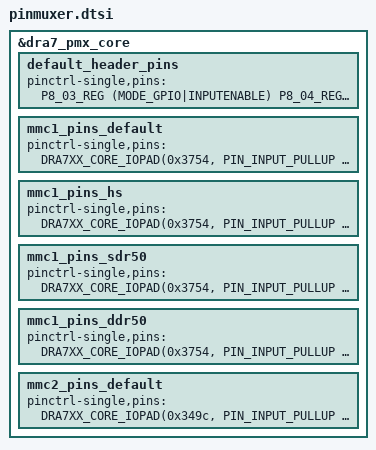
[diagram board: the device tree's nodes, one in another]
&dra7_pmx_core {
    //==============================================================================================
    //pin groups that are accessible via the headers -----------------------------------------------
    //==============================================================================================

    // Default grp: set all unused to GPIO (in). If you want to use any pin in a different way, 
    // comment it out here, put it in a different grp, and then connect the grp to a device in
    // the tree

    &default_header_pins: default_header_pins {  
        pinctrl-single,pins = < 
            P8_03_REG (MODE_GPIO|INPUTENABLE)
            P8_04_REG (MODE_GPIO|INPUTENABLE)
            P8_05_REG (MODE_GPIO|INPUTENABLE)
            P8_06_REG (MODE_GPIO|INPUTENABLE)
            P8_07_REG (MODE_GPIO|INPUTENABLE)
            P8_08_REG (MODE_GPIO|INPUTENABLE)
            P8_09_REG (MODE_GPIO|INPUTENABLE)
            P8_10_REG (MODE_GPIO|INPUTENABLE)

            P8_11_REG (MODE_GPIO|INPUTENABLE)
            P8_12_REG (MODE_GPIO|INPUTENABLE)
            P8_13_REG (MODE_GPIO|INPUTENABLE)
            P8_14_REG (MODE_GPIO|INPUTENABLE)
            P8_15A_REG (MODE_GPIO|INPUTENABLE)
            P8_15B_REG (MODE_OFF)
            P8_16_REG (MODE_GPIO|INPUTENABLE)
            P8_17_REG (MODE_GPIO|INPUTENABLE)
            P8_18_REG (MODE_GPIO|INPUTENABLE)
            P8_19_REG (MODE_GPIO|INPUTENABLE)

            P8_20_REG (MODE_GPIO|INPUTENABLE)
            P8_21_REG (MODE_GPIO|INPUTENABLE)
            P8_22_REG (MODE_GPIO|INPUTENABLE)
            P8_23_REG (MODE_GPIO|INPUTENABLE)
            P8_24_REG (MODE_GPIO|INPUTENABLE)
            P8_25_REG (MODE_GPIO|INPUTENABLE)
            P8_26_REG (MODE_GPIO|INPUTENABLE)
            P8_27A_REG (MODE_GPIO|INPUTENABLE)
            P8_27B_REG (MODE_OFF)
            P8_28A_REG (MODE_GPIO|INPUTENABLE)
            P8_28B_REG (MODE_OFF)
            P8_29A_REG (MODE_GPIO|INPUTENABLE)
            P8_29B_REG (MODE_OFF)

            P8_30A_REG (MODE_GPIO|INPUTENABLE)
            P8_30B_REG (MODE_OFF)
            P8_31A_REG (MODE_GPIO|INPUTENABLE)
            P8_31B_REG (MODE_OFF)
            P8_32A_REG (MODE_GPIO|INPUTENABLE)
            P8_32B_REG (MODE_OFF)
            P8_33A_REG (MODE_GPIO|INPUTENABLE)
            P8_33B_REG (MODE_OFF)
            P8_34A_REG (MODE_GPIO|INPUTENABLE)
            P8_34B_REG (MODE_OFF)
            P8_35A_REG (MODE_GPIO|INPUTENABLE)
            P8_35B_REG (MODE_OFF)
            P8_36A_REG (MODE_GPIO|INPUTENABLE)
            P8_36B_REG (MODE_OFF)
            P8_37A_REG (MODE_GPIO|INPUTENABLE)
            P8_37B_REG (MODE_OFF)
            P8_38A_REG (MODE_GPIO|INPUTENABLE)
            P8_38B_REG (MODE_OFF)
            P8_39_REG  (MODE_GPIO|INPUTENABLE)

            P8_40_REG (MODE_GPIO|INPUTENABLE)
            P8_41_REG (MODE_GPIO|INPUTENABLE)
            P8_42_REG (MODE_GPIO|INPUTENABLE)
            P8_43_REG (MODE_GPIO|INPUTENABLE)
            P8_44_REG (MODE_GPIO|INPUTENABLE)
            P8_45A_REG (MODE_GPIO|INPUTENABLE)
            P8_45B_REG (MODE_OFF)
            P8_46A_REG (MODE_GPIO|INPUTENABLE)
            P8_46B_REG (MODE_OFF)

            P9_11A_REG (MODE_GPIO|INPUTENABLE)
            P9_11B_REG (MODE_OFF)
            P9_12_REG (MODE_GPIO|INPUTENABLE)
            P9_13A_REG (MODE_GPIO|INPUTENABLE)
            P9_13B_REG (MODE_OFF)
            P9_14_REG (MODE_GPIO|INPUTENABLE)
            P9_15_REG (MODE_GPIO|INPUTENABLE)
            P9_16_REG (MODE_GPIO|INPUTENABLE)
            P9_17A_REG (MODE_GPIO|INPUTENABLE)
            P9_17B_REG (MODE_OFF)
            P9_18A_REG (MODE_GPIO|INPUTENABLE)
            P9_18B_REG (MODE_OFF)
            P9_19A_REG (MODE_GPIO|INPUTENABLE)
            P9_19B_REG (MODE_OFF)

            P9_20A_REG (MODE_GPIO|INPUTENABLE)
            P9_20B_REG (MODE_OFF)
            P9_21A_REG (MODE_GPIO|INPUTENABLE)
            P9_21B_REG (MODE_OFF)
            P9_22A_REG (MODE_GPIO|INPUTENABLE)
            P9_22B_REG (MODE_OFF)
            P9_23_REG (MODE_GPIO|INPUTENABLE)
            P9_24_REG (MODE_GPIO|INPUTENABLE)
            P9_25_REG (MODE_GPIO|INPUTENABLE)
            P9_26A_REG (MODE_GPIO|INPUTENABLE)
            P9_26B_REG (MODE_OFF)
            P9_27A_REG (MODE_GPIO|INPUTENABLE)
            P9_27B_REG (MODE_OFF)
            P9_28_REG (MODE_GPIO|INPUTENABLE)
            P9_29A_REG (MODE_GPIO|INPUTENABLE)
            P9_29B_REG (MODE_OFF)
            P9_30_REG (MODE_GPIO|INPUTENABLE)

            P9_31A_REG (MODE_GPIO|INPUTENABLE)
            P9_31B_REG (MODE_OFF)

            P9_41A_REG (MODE_GPIO|INPUTENABLE)
            P9_41B_REG (MODE_OFF)
            P9_42A_REG (MODE_GPIO|INPUTENABLE)
            P9_42B_REG (MODE_OFF)
    >;
    };

    //==============================================================================================
    //pin groups, that are reserved by some device in the tree but not accessible via the headers -- 
    //==============================================================================================
    
    mmc1_pins_default: mmc1_pins_default {
        pinctrl-single,pins = <
            DRA7XX_CORE_IOPAD(0x3754, PIN_INPUT_PULLUP | MUX_MODE0)
            DRA7XX_CORE_IOPAD(0x3758, PIN_INPUT_PULLUP | MUX_MODE0)
            DRA7XX_CORE_IOPAD(0x375c, PIN_INPUT_PULLUP | MUX_MODE0)
            DRA7XX_CORE_IOPAD(0x3760, PIN_INPUT_PULLUP | MUX_MODE0)
            DRA7XX_CORE_IOPAD(0x3764, PIN_INPUT_PULLUP | MUX_MODE0)
            DRA7XX_CORE_IOPAD(0x3768, PIN_INPUT_PULLUP | MUX_MODE0)
        >;
    };

    mmc1_pins_hs: mmc1_pins_hs {
        pinctrl-single,pins = <
            DRA7XX_CORE_IOPAD(0x3754, PIN_INPUT_PULLUP | MUX_VIRTUAL_MODE11 | MUX_MODE0)
            DRA7XX_CORE_IOPAD(0x3758, PIN_INPUT_PULLUP | MUX_VIRTUAL_MODE11 | MUX_MODE0)
            DRA7XX_CORE_IOPAD(0x375c, PIN_INPUT_PULLUP | MUX_VIRTUAL_MODE11 | MUX_MODE0)
            DRA7XX_CORE_IOPAD(0x3760, PIN_INPUT_PULLUP | MUX_VIRTUAL_MODE11 | MUX_MODE0)
            DRA7XX_CORE_IOPAD(0x3764, PIN_INPUT_PULLUP | MUX_VIRTUAL_MODE11 | MUX_MODE0)
            DRA7XX_CORE_IOPAD(0x3768, PIN_INPUT_PULLUP | MUX_VIRTUAL_MODE11 | MUX_MODE0)
        >;
    };

    mmc1_pins_sdr50: mmc1_pins_sdr50 {
        pinctrl-single,pins = <
            DRA7XX_CORE_IOPAD(0x3754, PIN_INPUT_PULLUP | MUX_VIRTUAL_MODE10 | MUX_MODE0)
            DRA7XX_CORE_IOPAD(0x3758, PIN_INPUT_PULLUP | MUX_VIRTUAL_MODE10 | MUX_MODE0)
            DRA7XX_CORE_IOPAD(0x375c, PIN_INPUT_PULLUP | MUX_VIRTUAL_MODE10 | MUX_MODE0)
            DRA7XX_CORE_IOPAD(0x3760, PIN_INPUT_PULLUP | MUX_VIRTUAL_MODE10 | MUX_MODE0)
            DRA7XX_CORE_IOPAD(0x3764, PIN_INPUT_PULLUP | MUX_VIRTUAL_MODE10 | MUX_MODE0)
            DRA7XX_CORE_IOPAD(0x3768, PIN_INPUT_PULLUP | MUX_VIRTUAL_MODE10 | MUX_MODE0)
        >;
    };

    mmc1_pins_ddr50: mmc1_pins_ddr50 {
        pinctrl-single,pins = <
            DRA7XX_CORE_IOPAD(0x3754, PIN_INPUT_PULLUP | MODE_SELECT | MUX_MODE0)
            DRA7XX_CORE_IOPAD(0x3758, PIN_INPUT_PULLUP | MODE_SELECT | MUX_MODE0)
            DRA7XX_CORE_IOPAD(0x375c, PIN_INPUT_PULLUP | MODE_SELECT | MUX_MODE0)
            DRA7XX_CORE_IOPAD(0x3760, PIN_INPUT_PULLUP | MODE_SELECT | MUX_MODE0)
            DRA7XX_CORE_IOPAD(0x3764, PIN_INPUT_PULLUP | MODE_SELECT | MUX_MODE0)
            DRA7XX_CORE_IOPAD(0x3768, PIN_INPUT_PULLUP | MODE_SELECT | MUX_MODE0)
        >;
    };

    mmc2_pins_default: mmc2_pins_default {
        pinctrl-single,pins = <
            DRA7XX_CORE_IOPAD(0x349c, PIN_INPUT_PULLUP | MUX_MODE1)
            DRA7XX_CORE_IOPAD(0x34b0, PIN_INPUT_PULLUP | MUX_MODE1)
            DRA7XX_CORE_IOPAD(0x34a0, PIN_INPUT_PULLUP | MUX_MODE1)
            DRA7XX_CORE_IOPAD(0x34a4, PIN_INPUT_PULLUP | MUX_MODE1)
            DRA7XX_CORE_IOPAD(0x34a8, PIN_INPUT_PULLUP | MUX_MODE1)
            DRA7XX_CORE_IOPAD(0x34ac, PIN_INPUT_PULLUP | MUX_MODE1)
            DRA7XX_CORE_IOPAD(0x348c, PIN_INPUT_PULLUP | MUX_MODE1)
            DRA7XX_CORE_IOPAD(0x3490, PIN_INPUT_PULLUP | MUX_MODE1)
            DRA7XX_CORE_IOPAD(0x3494, PIN_INPUT_PULLUP | MUX_MODE1)
            DRA7XX_CORE_IOPAD(0x3498, PIN_INPUT_PULLUP | MUX_MODE1)
        >;
    };

};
